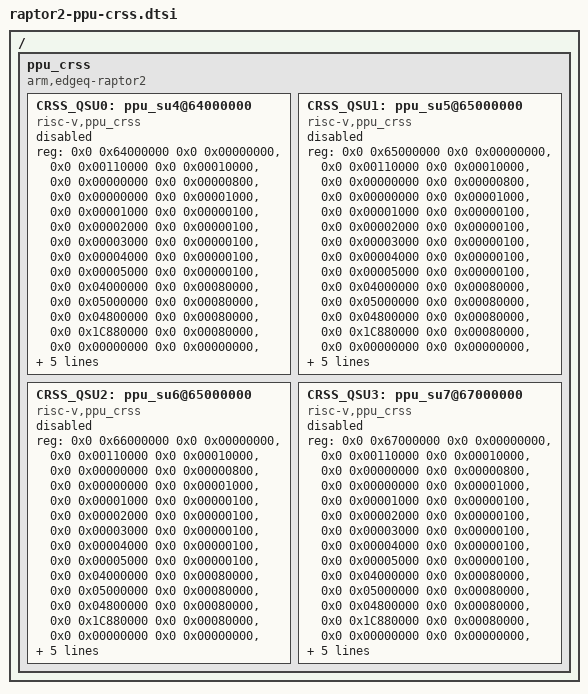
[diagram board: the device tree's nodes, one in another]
// SPDX-License-Identifier: GPL-2.0
/*
 * EdgeQ Inc.
 *
 * EdgeQ Raptor2 PPU_CRSS DTSI
 */

/ {

	ppu_crss {
		compatible = "arm,edgeq-raptor2";
		#address-cells = <2>;
		#size-cells = <2>;

		CRSS_QSU0: ppu_su4@64000000 {
			compatible = "risc-v,ppu_crss";
			device_type = "su";
			#address-cells = <2>;
			#size-cells = <2>;
			ranges;
			reg =	<0x0 0x64000000 0x0 0x00000000>,
				<0x0 0x00110000 0x0 0x00010000>,
				<0x0 0x00000000 0x0 0x00000800>,
				<0x0 0x00000000 0x0 0x00001000>,
				<0x0 0x00001000 0x0 0x00000100>,
				<0x0 0x00002000 0x0 0x00000100>,
				<0x0 0x00003000 0x0 0x00000100>,
				<0x0 0x00004000 0x0 0x00000100>,
				<0x0 0x00005000 0x0 0x00000100>,
				<0x0 0x04000000 0x0 0x00080000>,
				<0x0 0x05000000 0x0 0x00080000>,
				<0x0 0x04800000 0x0 0x00080000>,
				<0x0 0x1C880000 0x0 0x00080000>,
				<0x0 0x00000000 0x0 0x00000000>,
				<0x0 0x00000000 0x0 0x00004000>,
				<0x0 0x00080000 0x0 0x00004000>;
			reg-names = "sudev_base", "cpu", "d-cache", "i-cache", "suinfo_offset",
				"suconf_offset", "suau_offset", "sustats_offset", "sudbg_offset",
				"lmem_addr_local_wb", "lmem_addr_local_unc", "lmem_addr_local_wt",
				"lmem_e1", "lmem_e1_b2", "ilmoffs", "dlmoffs";
			enable-method = "reset-vector";
			sudev = <&SUDEV>;
			sumem = <&SUMEM>;
			status = "disabled";
		};

		CRSS_QSU1: ppu_su5@65000000 {
			compatible = "risc-v,ppu_crss";
			device_type = "su";
			#address-cells = <2>;
			#size-cells = <2>;
			ranges;
			reg =	<0x0 0x65000000 0x0 0x00000000>,
				<0x0 0x00110000 0x0 0x00010000>,
				<0x0 0x00000000 0x0 0x00000800>,
				<0x0 0x00000000 0x0 0x00001000>,
				<0x0 0x00001000 0x0 0x00000100>,
				<0x0 0x00002000 0x0 0x00000100>,
				<0x0 0x00003000 0x0 0x00000100>,
				<0x0 0x00004000 0x0 0x00000100>,
				<0x0 0x00005000 0x0 0x00000100>,
				<0x0 0x04000000 0x0 0x00080000>,
				<0x0 0x05000000 0x0 0x00080000>,
				<0x0 0x04800000 0x0 0x00080000>,
				<0x0 0x1C880000 0x0 0x00080000>,
				<0x0 0x00000000 0x0 0x00000000>,
				<0x0 0x00000000 0x0 0x00004000>,
				<0x0 0x00080000 0x0 0x00004000>;
			reg-names = "sudev_base", "cpu", "d-cache", "i-cache", "suinfo_offset",
				"suconf_offset", "suau_offset", "sustats_offset", "sudbg_offset",
				"lmem_addr_local_wb", "lmem_addr_local_unc", "lmem_addr_local_wt",
				"lmem_e1", "lmem_e1_b2", "ilmoffs", "dlmoffs";
			enable-method = "reset-vector";
			sudev = <&SUDEV>;
			sumem = <&SUMEM>;
			status = "disabled";
		};

		CRSS_QSU2: ppu_su6@65000000 {
			compatible = "risc-v,ppu_crss";
			device_type = "su";
			#address-cells = <2>;
			#size-cells = <2>;
			ranges;
			reg =	<0x0 0x66000000 0x0 0x00000000>,
				<0x0 0x00110000 0x0 0x00010000>,
				<0x0 0x00000000 0x0 0x00000800>,
				<0x0 0x00000000 0x0 0x00001000>,
				<0x0 0x00001000 0x0 0x00000100>,
				<0x0 0x00002000 0x0 0x00000100>,
				<0x0 0x00003000 0x0 0x00000100>,
				<0x0 0x00004000 0x0 0x00000100>,
				<0x0 0x00005000 0x0 0x00000100>,
				<0x0 0x04000000 0x0 0x00080000>,
				<0x0 0x05000000 0x0 0x00080000>,
				<0x0 0x04800000 0x0 0x00080000>,
				<0x0 0x1C880000 0x0 0x00080000>,
				<0x0 0x00000000 0x0 0x00000000>,
				<0x0 0x00000000 0x0 0x00004000>,
				<0x0 0x00080000 0x0 0x00004000>;
			reg-names = "sudev_base", "cpu", "d-cache", "i-cache", "suinfo_offset",
				"suconf_offset", "suau_offset", "sustats_offset", "sudbg_offset",
				"lmem_addr_local_wb", "lmem_addr_local_unc", "lmem_addr_local_wt",
				"lmem_e1", "lmem_e1_b2", "ilmoffs", "dlmoffs";
			enable-method = "reset-vector";
			sudev = <&SUDEV>;
			sumem = <&SUMEM>;
			status = "disabled";
		};

		CRSS_QSU3: ppu_su7@67000000 {
			compatible = "risc-v,ppu_crss";
			device_type = "su";
			#address-cells = <2>;
			#size-cells = <2>;
			ranges;
			reg =	<0x0 0x67000000 0x0 0x00000000>,
				<0x0 0x00110000 0x0 0x00010000>,
				<0x0 0x00000000 0x0 0x00000800>,
				<0x0 0x00000000 0x0 0x00001000>,
				<0x0 0x00001000 0x0 0x00000100>,
				<0x0 0x00002000 0x0 0x00000100>,
				<0x0 0x00003000 0x0 0x00000100>,
				<0x0 0x00004000 0x0 0x00000100>,
				<0x0 0x00005000 0x0 0x00000100>,
				<0x0 0x04000000 0x0 0x00080000>,
				<0x0 0x05000000 0x0 0x00080000>,
				<0x0 0x04800000 0x0 0x00080000>,
				<0x0 0x1C880000 0x0 0x00080000>,
				<0x0 0x00000000 0x0 0x00000000>,
				<0x0 0x00000000 0x0 0x00004000>,
				<0x0 0x00080000 0x0 0x00004000>;
			reg-names = "sudev_base", "cpu", "d-cache", "i-cache", "suinfo_offset",
				"suconf_offset", "suau_offset", "sustats_offset", "sudbg_offset",
				"lmem_addr_local_wb", "lmem_addr_local_unc", "lmem_addr_local_wt",
				"lmem_e1", "lmem_e1_b2", "ilmoffs", "dlmoffs";
			enable-method = "reset-vector";
			sudev = <&SUDEV>;
			sumem = <&SUMEM>;
			status = "disabled";
		};
	};
};
